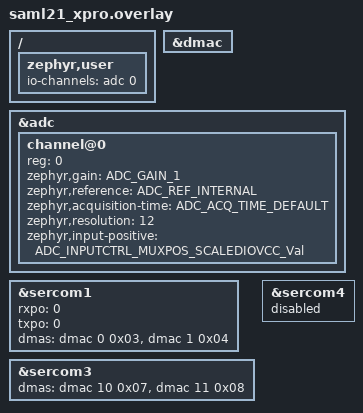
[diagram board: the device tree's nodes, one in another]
/*
 * Copyright (c) 2022 Kumar Gala <galak@kernel.org>
 *
 * SPDX-License-Identifier: Apache-2.0
 */

tst_dma0: &dmac {
	status = "okay";
};

#define ADC_INPUTCTRL_MUXPOS_SCALEDIOVCC_Val 0x1BU

/ {
	zephyr,user {
		io-channels = <&adc 0>;
	};
};

&adc {
	#address-cells = <1>;
	#size-cells = <0>;
	channel@0 {
		reg = <0>;
		zephyr,gain = "ADC_GAIN_1";
		zephyr,reference = "ADC_REF_INTERNAL";
		zephyr,acquisition-time = <ADC_ACQ_TIME_DEFAULT>;
		zephyr,resolution = <12>;
		zephyr,input-positive = <ADC_INPUTCTRL_MUXPOS_SCALEDIOVCC_Val>;
	};
};

&dmac {
	status = "okay";
};

dut: &sercom1 {
	rxpo = <0>;
	txpo = <0>;
	dmas = <&dmac 0 0x03>, <&dmac 1 0x04>;
	dma-names = "rx", "tx";
};

&sercom3 {
	dmas = <&dmac 10 0x07>, <&dmac 11 0x08>;
	dma-names = "rx", "tx";
};

&sercom4 {
	status = "disabled";
};
